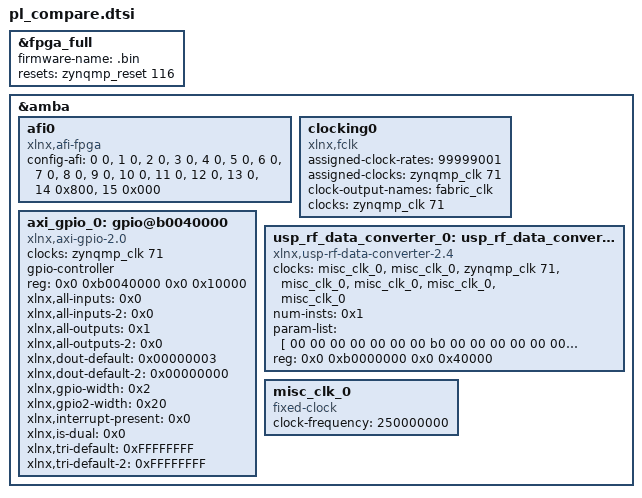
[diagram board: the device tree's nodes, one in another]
/*
 * CAUTION: This file is automatically generated by Xilinx.
 * Version: XSCT 2020.2
 * Today is: Thu Apr 15 23:26:25 2021
 */


/dts-v1/;
/plugin/;
/ {
	fragment@0 {
		target = <&fpga_full>;
		overlay0: __overlay__ {
			#address-cells = <2>;
			#size-cells = <2>;
			firmware-name = ".bin";
			resets = <&zynqmp_reset 116>;
		};
	};
	fragment@1 {
		target = <&amba>;
		overlay1: __overlay__ {
			afi0: afi0 {
				compatible = "xlnx,afi-fpga";
				config-afi = < 0 0>, <1 0>, <2 0>, <3 0>, <4 0>, <5 0>, <6 0>, <7 0>, <8 0>, <9 0>, <10 0>, <11 0>, <12 0>, <13 0>, <14 0x800>, <15 0x000>;
			};
			clocking0: clocking0 {
				#clock-cells = <0>;
				assigned-clock-rates = <99999001>;
				assigned-clocks = <&zynqmp_clk 71>;
				clock-output-names = "fabric_clk";
				clocks = <&zynqmp_clk 71>;
				compatible = "xlnx,fclk";
			};
		};
	};
	fragment@2 {
		target = <&amba>;
		overlay2: __overlay__ {
			#address-cells = <2>;
			#size-cells = <2>;
			axi_gpio_0: gpio@b0040000 {
				#gpio-cells = <3>;
				clock-names = "s_axi_aclk";
				clocks = <&zynqmp_clk 71>;
				compatible = "xlnx,axi-gpio-2.0", "xlnx,xps-gpio-1.00.a";
				gpio-controller ;
				reg = <0x0 0xb0040000 0x0 0x10000>;
				xlnx,all-inputs = <0x0>;
				xlnx,all-inputs-2 = <0x0>;
				xlnx,all-outputs = <0x1>;
				xlnx,all-outputs-2 = <0x0>;
				xlnx,dout-default = <0x00000003>;
				xlnx,dout-default-2 = <0x00000000>;
				xlnx,gpio-width = <0x2>;
				xlnx,gpio2-width = <0x20>;
				xlnx,interrupt-present = <0x0>;
				xlnx,is-dual = <0x0>;
				xlnx,tri-default = <0xFFFFFFFF>;
				xlnx,tri-default-2 = <0xFFFFFFFF>;
			};
			usp_rf_data_converter_0: usp_rf_data_converter@b0000000 {
				clock-names = "adc2_clk_p", "adc2_clk_n", "s_axi_aclk", "m0_axis_aclk", "m1_axis_aclk", "m2_axis_aclk", "m3_axis_aclk";
				clocks = <&misc_clk_0>, <&misc_clk_0>, <&zynqmp_clk 71>, <&misc_clk_0>, <&misc_clk_0>, <&misc_clk_0>, <&misc_clk_0>;
				compatible = "xlnx,usp-rf-data-converter-2.4";
				num-insts = <0x1>;
				param-list = [ 00 00 00 00 00 00 00 b0 00 00 00 00 00 00 00 00 00 00 00 00 00 00 00 00 01 00 00 00 01 00 00 00 02 00 00 00 00 00 00 00 00 00 00 00 00 00 00 00 9a 99 99 99 99 99 19 40 00 00 00 00 00 00 b9 40 00 00 00 00 00 00 00 00 0a 00 00 00 02 00 00 00 01 00 00 00 00 00 00 00 00 00 00 00 00 00 24 40 04 00 00 00 00 00 00 00 00 00 00 00 02 00 00 00 00 00 00 00 00 00 00 00 00 00 00 00 02 00 00 00 00 00 00 00 00 00 00 00 00 00 00 00 02 00 00 00 00 00 00 00 00 00 00 00 00 00 00 00 02 00 00 00 00 00 00 00 00 00 00 00 10 00 00 00 00 00 00 00 00 00 00 00 00 00 00 00 03 00 00 00 00 00 00 00 10 00 00 00 00 00 00 00 00 00 00 00 00 00 00 00 03 00 00 00 00 00 00 00 10 00 00 00 00 00 00 00 00 00 00 00 00 00 00 00 03 00 00 00 00 00 00 00 10 00 00 00 00 00 00 00 00 00 00 00 00 00 00 00 03 00 00 00 00 00 00 00 00 00 00 00 9a 99 99 99 99 99 19 40 00 00 00 00 00 00 b9 40 00 00 00 00 00 00 00 00 0a 00 00 00 02 00 00 00 01 00 00 00 00 00 00 00 00 00 00 00 00 00 24 40 04 00 00 00 00 00 00 00 00 00 00 00 02 00 00 00 00 00 00 00 00 00 00 00 00 00 00 00 02 00 00 00 00 00 00 00 00 00 00 00 00 00 00 00 02 00 00 00 00 00 00 00 00 00 00 00 00 00 00 00 02 00 00 00 00 00 00 00 00 00 00 00 10 00 00 00 00 00 00 00 00 00 00 00 00 00 00 00 03 00 00 00 00 00 00 00 10 00 00 00 00 00 00 00 00 00 00 00 00 00 00 00 03 00 00 00 00 00 00 00 10 00 00 00 00 00 00 00 00 00 00 00 00 00 00 00 03 00 00 00 00 00 00 00 10 00 00 00 00 00 00 00 00 00 00 00 00 00 00 00 03 00 00 00 00 00 00 00 00 00 00 00 9a 99 99 99 99 99 19 40 00 00 00 00 00 00 b9 40 00 00 00 00 00 00 00 00 0a 00 00 00 02 00 00 00 01 00 00 00 00 00 00 00 00 00 00 00 00 00 24 40 04 00 00 00 00 00 00 00 00 00 00 00 02 00 00 00 00 00 00 00 00 00 00 00 00 00 00 00 02 00 00 00 00 00 00 00 00 00 00 00 00 00 00 00 02 00 00 00 00 00 00 00 00 00 00 00 00 00 00 00 02 00 00 00 00 00 00 00 00 00 00 00 10 00 00 00 00 00 00 00 00 00 00 00 00 00 00 00 03 00 00 00 00 00 00 00 10 00 00 00 00 00 00 00 00 00 00 00 00 00 00 00 03 00 00 00 00 00 00 00 10 00 00 00 00 00 00 00 00 00 00 00 00 00 00 00 03 00 00 00 00 00 00 00 10 00 00 00 00 00 00 00 00 00 00 00 00 00 00 00 03 00 00 00 00 00 00 00 00 00 00 00 9a 99 99 99 99 99 19 40 00 00 00 00 00 00 b9 40 00 00 00 00 00 00 00 00 0a 00 00 00 02 00 00 00 01 00 00 00 00 00 00 00 00 00 00 00 00 00 24 40 04 00 00 00 00 00 00 00 00 00 00 00 02 00 00 00 00 00 00 00 00 00 00 00 00 00 00 00 02 00 00 00 00 00 00 00 00 00 00 00 00 00 00 00 02 00 00 00 00 00 00 00 00 00 00 00 00 00 00 00 02 00 00 00 00 00 00 00 00 00 00 00 10 00 00 00 00 00 00 00 00 00 00 00 00 00 00 00 03 00 00 00 00 00 00 00 10 00 00 00 00 00 00 00 00 00 00 00 00 00 00 00 03 00 00 00 00 00 00 00 10 00 00 00 00 00 00 00 00 00 00 00 00 00 00 00 03 00 00 00 00 00 00 00 10 00 00 00 00 00 00 00 00 00 00 00 00 00 00 00 03 00 00 00 01 00 00 00 01 00 00 00 00 00 00 00 00 00 00 40 00 00 00 00 00 40 6f 40 00 00 00 00 00 40 6f 40 30 00 00 00 06 00 00 00 01 00 00 00 00 00 00 00 00 00 00 00 00 00 04 40 04 00 00 00 01 00 00 00 02 00 00 00 00 00 00 00 02 00 00 00 00 00 00 00 02 00 00 00 00 00 00 00 02 00 00 00 00 00 00 00 01 00 00 00 08 00 00 00 00 00 00 00 01 00 00 00 00 00 00 00 08 00 00 00 00 00 00 00 00 00 00 00 03 00 00 00 00 00 00 00 08 00 00 00 00 00 00 00 00 00 00 00 03 00 00 00 00 00 00 00 08 00 00 00 00 00 00 00 00 00 00 00 03 00 00 00 01 00 00 00 01 00 00 00 00 00 00 00 00 00 00 40 00 00 00 00 00 40 6f 40 00 00 00 00 00 40 6f 40 30 00 00 00 06 00 00 00 01 00 00 00 00 00 00 00 00 00 00 00 00 00 04 40 04 00 00 00 01 00 00 00 02 00 00 00 00 00 00 00 02 00 00 00 00 00 00 00 02 00 00 00 00 00 00 00 02 00 00 00 00 00 00 00 01 00 00 00 08 00 00 00 00 00 00 00 01 00 00 00 00 00 00 00 08 00 00 00 00 00 00 00 00 00 00 00 03 00 00 00 00 00 00 00 08 00 00 00 00 00 00 00 00 00 00 00 03 00 00 00 00 00 00 00 08 00 00 00 00 00 00 00 00 00 00 00 03 00 00 00 01 00 00 00 01 00 00 00 00 00 00 00 00 00 00 40 00 00 00 00 00 40 6f 40 00 00 00 00 00 40 6f 40 30 00 00 00 06 00 00 00 01 00 00 00 00 00 00 00 00 00 00 00 00 00 04 40 04 00 00 00 01 00 00 00 02 00 00 00 00 00 00 00 02 00 00 00 00 00 00 00 02 00 00 00 00 00 00 00 02 00 00 00 00 00 00 00 01 00 00 00 08 00 00 00 00 00 00 00 01 00 00 00 00 00 00 00 08 00 00 00 00 00 00 00 00 00 00 00 03 00 00 00 00 00 00 00 08 00 00 00 00 00 00 00 00 00 00 00 03 00 00 00 00 00 00 00 08 00 00 00 00 00 00 00 00 00 00 00 03 00 00 00 01 00 00 00 01 00 00 00 00 00 00 00 00 00 00 40 00 00 00 00 00 40 6f 40 00 00 00 00 00 40 6f 40 30 00 00 00 06 00 00 00 01 00 00 00 00 00 00 00 00 00 00 00 00 00 04 40 04 00 00 00 01 00 00 00 02 00 00 00 00 00 00 00 02 00 00 00 00 00 00 00 02 00 00 00 00 00 00 00 02 00 00 00 00 00 00 00 01 00 00 00 08 00 00 00 00 00 00 00 01 00 00 00 00 00 00 00 08 00 00 00 00 00 00 00 00 00 00 00 03 00 00 00 00 00 00 00 08 00 00 00 00 00 00 00 00 00 00 00 03 00 00 00 00 00 00 00 08 00 00 00 00 00 00 00 00 00 00 00 03 00 00 00];
				reg = <0x0 0xb0000000 0x0 0x40000>;
			};
			misc_clk_0: misc_clk_0 {
				#clock-cells = <0>;
				clock-frequency = <250000000>;
				compatible = "fixed-clock";
			};
		};
	};
};
